# STM32U335 register map
File version: 1.0
CPU: CM33 r0p1, little endian, MPU, FPU, 4 interrupt priority bits
Registers are 32-bit, read-write, reset 0x0 unless marked. A register's access mark holds for its fields unless they carry their own. Offsets are from the block's base; [hi:lo] are bit positions.

## GTZC1_TZIC — GTZC1_TZIC Address block
Base 0x40032800
Same registers: GTZC1_TZIC_S 0x50032800
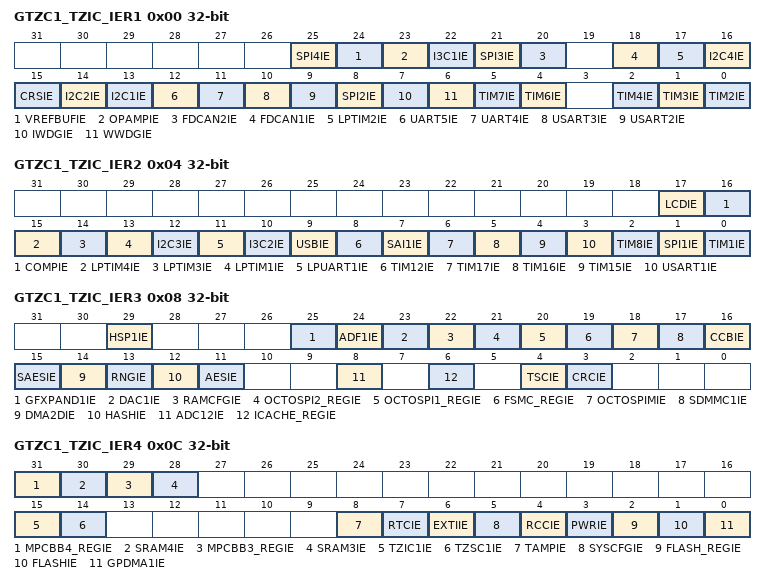
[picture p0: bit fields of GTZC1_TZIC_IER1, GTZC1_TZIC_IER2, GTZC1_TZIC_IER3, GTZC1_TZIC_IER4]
0x00 GTZC1_TZIC_IER1 — Secure privileged access only. This register is used to enable interrupt of illegal access. This register is used to enable interrupt of illegal access.
  [all] fields
    0=interrupt disabled; 1=interrupt enabled
  [25] SPI4IE — illegal access interrupt enable for SPI4 Note: this bit is only available on STM32U3B5/3C5.
  [24] VREFBUFIE — illegal access interrupt enable for VREFBUF Note: this bit is not available on STM32U335/345.
  [23] OPAMPIE — illegal access interrupt enable for OPAMP
  [22] I3C1IE — illegal access interrupt enable for I3C1
  [21] SPI3IE — illegal access interrupt enable for SPI3 Note: this bit is not available on STM32U335/345.
  [20] FDCAN2IE — illegal access interrupt enable for FDCAN2 Note: This bit is only available on STM32U3B5/3C5.
  [18] FDCAN1IE — illegal access interrupt enable for FDCAN1 Note: This bit is not available on STM32U356/366.
  [17] LPTIM2IE — illegal access interrupt enable for LPTIM2
  [16] I2C4IE — illegal access interrupt enable for I2C4 Note: This bit is only available on STM32U3B5/3C5.
  [15] CRSIE — illegal access interrupt enable for CRS
  [14] I2C2IE — illegal access interrupt enable for I2C2 Note: This bit is only available on STM32U375/385, STM32U396/3A6, and STM32U3B5/3C5.
  [13] I2C1IE — illegal access interrupt enable for I2C1
  [12] UART5IE — illegal access interrupt enable for UART5 Note: this bit is not available on STM32U335/345.
  [11] UART4IE — illegal access interrupt enable for UART4
  [10] USART3IE — illegal access interrupt enable for USART3
  [9] USART2IE — illegal access interrupt enable for USART2 Note: This bit is only available on STM32U396/3A6 and STM32U3B5/3C5.
  [8] SPI2IE — illegal access interrupt enable for SPI2
  [7] IWDGIE — illegal access interrupt enable for IWDG
  [6] WWDGIE — illegal access interrupt enable for WWDG
  [5] TIM7IE — illegal access interrupt enable for TIM7 0: interrupt disabled 1: interrupt enabled
  [4] TIM6IE — illegal access interrupt enable for TIM6 0: interrupt disabled 1: interrupt enabled
  [2] TIM4IE — illegal access interrupt enable for TIM4 0: interrupt disabled 1: interrupt enabled
  [1] TIM3IE — illegal access interrupt enable for TIM3 0: interrupt disabled 1: interrupt enabled
  [0] TIM2IE — illegal access interrupt enable for TIM2 0: interrupt disabled 1: interrupt enabled
0x04 GTZC1_TZIC_IER2 — Secure privileged access only. This register is used to enable interrupt of illegal access. This register is used to enable interrupt of illegal access.
  [all] fields
    0=interrupt disabled; 1=interrupt enabled
  [17] LCDIE — illegal access interrupt enable for LCD Note: This bit is only available on STM32U356/366 and STM32U396/3A6.
  [16] COMPIE — illegal access interrupt enable for COMP
  [15] LPTIM4IE — illegal access interrupt enable for LPTIM4 0: interrupt disabled 1: interrupt enabled
  [14] LPTIM3IE — illegal access interrupt enable for LPTIM3 0: interrupt disabled 1: interrupt enabled
  [13] LPTIM1IE — illegal access interrupt enable for LPTIM1 0: interrupt disabled 1: interrupt enabled
  [12] I2C3IE — illegal access interrupt enable for I2C3
  [11] LPUART1IE — illegal access interrupt enable for LPUART1
  [10] I3C2IE — illegal access interrupt enable for I3C2 Note: This bit is only available on STM32U375/385, STM32U396/3A6, and STM32U3B5/3C5.
  [9] USBIE — illegal access interrupt enable for USB
  [8] TIM12IE — illegal access interrupt enable for TIM12 Note: This bit is only available on STM32U396/3A6 and STM32U3B5/3C5.
  [7] SAI1IE — illegal access interrupt enable for SAI1 Note: This bit is only available on STM32U375/385, STM32U396/3A6, and STM32U3B5/3C5.
  [6] TIM17IE — illegal access interrupt enable for TIM17 0: interrupt disabled 1: interrupt enabled
  [5] TIM16IE — illegal access interrupt enable for TIM16 0: interrupt disabled 1: interrupt enabled
  [4] TIM15IE — illegal access interrupt enable for TIM15 0: interrupt disabled 1: interrupt enabled
  [3] USART1IE — illegal access interrupt enable for USART1
  [2] TIM8IE — illegal access interrupt enable for TIM8 Note: This bit is only available on STM32U396/3A6, and STM32U3B5/3C5.
  [1] SPI1IE — illegal access interrupt enable for SPI1
  [0] TIM1IE — illegal access interrupt enable for TIM1 0: interrupt disabled 1: interrupt enabled
0x08 GTZC1_TZIC_IER3 — Secure privileged access only. This register is used to enable interrupt of illegal access. This register is used to enable interrupt of illegal access.
  [all] fields
    0=interrupt disabled; 1=interrupt enabled
  [29] HSP1IE — illegal access interrupt enable for HSP1 Note: This bit is only available on STM32U396/3A6 and STM32U3B5/3C5.
  [25] GFXPAND1IE — illegal access interrupt enable for GFXPAND1 Note: This bit is only available on STM32U396/3A6.
  [24] ADF1IE — illegal access interrupt enable for ADF1 Note: This bit is not available on STM32U356/366.
  [23] DAC1IE — illegal access interrupt enable for DAC1
  [22] RAMCFGIE — illegal access interrupt enable for RAMCFG
  [21] OCTOSPI2_REGIE — illegal access interrupt enable for OCTOSPI2 registers Note: This bit is only available on STM32U396/3A6.
  [20] OCTOSPI1_REGIE — illegal access interrupt enable for OCTOSPI1 registers
  [19] FSMC_REGIE — illegal access interrupt enable for FSMC registers Note: This bit is only available on STM32U396/3A6.
  [18] OCTOSPIMIE — illegal access interrupt enable for OCTOSPIM Note: This bit is only available on STM32U396/3A6.
  [17] SDMMC1IE — illegal access interrupt enable for SDMMC1 Note: This bit is only available on STM32U375/385, STM32U396/3A6, and STM32U3B5/3C5.
  [16] CCBIE — illegal access interrupt enable for CCB Note: This bit is not available on STM32U335/345.
  [15] SAESIE — illegal access interrupt enable for SAES Note: This bit is not available on STM32U335/345.
  [14] DMA2DIE — illegal access interrupt enable for DMA2D Note: This bit is only available on STM32U396/3A6.
  [13] RNGIE — illegal access interrupt enable for RNG
  [12] HASHIE — illegal access interrupt enable for HASH
  [11] AESIE — illegal access interrupt enable for AES
  [8] ADC12IE — illegal access interrupt enable for ADC1 and ADC2
  [6] ICACHE_REGIE — illegal access interrupt enable for ICACHE registers
  [4] TSCIE — illegal access interrupt enable for TSC
  [3] CRCIE — illegal access interrupt enable for CRC
0x0C GTZC1_TZIC_IER4 — Secure privileged access only. This register is used to enable interrupt of illegal access. This register is used to enable interrupt of illegal access.
  [all] fields
    0=interrupt disabled; 1=interrupt enabled
  [31] MPCBB4_REGIE — illegal access interrupt enable for MPCBB4 registers 0: interrupt disabled 1: interrupt enabled Note: This bit is only available on STM32U396/3A6 and STM32U3B5/3C5.
  [30] SRAM4IE — illegal access interrupt enable for SRAM4 0: interrupt disabled 1: interrupt enabled Note: This bit is only available on STM32U396/3A6 and STM32U3B5/3C5.
  [29] MPCBB3_REGIE — illegal access interrupt enable for MPCBB3 registers 0: interrupt disabled 1: interrupt enabled Note: This bit is only available on STM32U396/3A6 and STM32U3B5/3C5.
  [28] SRAM3IE — illegal access interrupt enable for SRAM3 0: interrupt disabled 1: interrupt enabled Note: This bit is only available on STM32U396/3A6 and STM32U3B5/3C5.
  [15] TZIC1IE — illegal access interrupt enable for GTZC1 TZIC registers
  [14] TZSC1IE — illegal access interrupt enable for GTZC1 TZSC registers
  [8] TAMPIE — illegal access interrupt enable for TAMP
  [7] RTCIE — illegal access interrupt enable for RTC
  [6] EXTIIE — illegal access interrupt enable for EXTI
  [5] SYSCFGIE — illegal access interrupt enable for SYSCFG
  [4] RCCIE — illegal access interrupt enable for RCC
  [3] PWRIE — illegal access interrupt enable for PWR
  [2] FLASH_REGIE — illegal access interrupt enable for FLASH registers
  [1] FLASHIE — illegal access interrupt enable for FLASH memory
  [0] GPDMA1IE — illegal access interrupt enable for GPDMA1
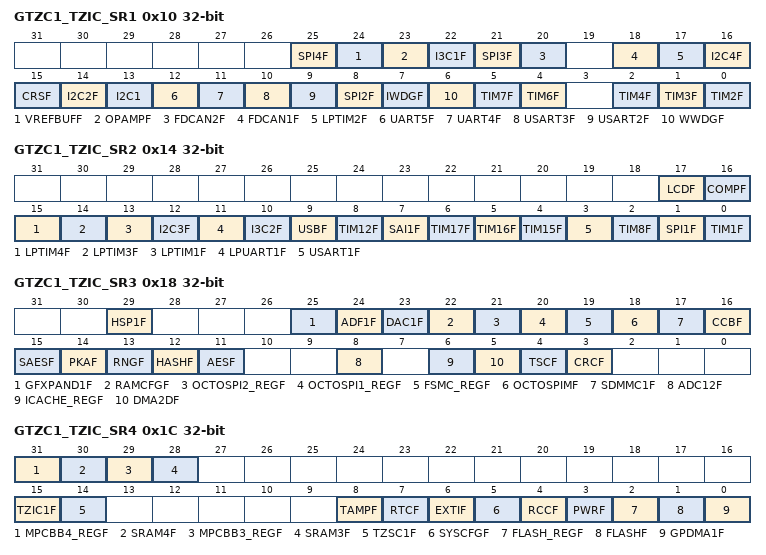
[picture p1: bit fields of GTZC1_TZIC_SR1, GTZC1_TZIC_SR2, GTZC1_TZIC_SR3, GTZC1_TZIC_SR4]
0x10 GTZC1_TZIC_SR1 — Secure privileged access only.
  [all] fields
    0=no illegal access event; 1=illegal access event
  [25] SPI4F — illegal access flag for SPI4 Note: this bit is only available on STM32U3B5/3C5.
  [24] VREFBUFF — illegal access flag for VREFBUF Note: this bit is not available on STM32U335/345.
  [23] OPAMPF — illegal access flag for OPAMP
  [22] I3C1F — illegal access flag for I3C1
  [21] SPI3F — illegal access flag for SPI3 Note: this bit is not available on STM32U335/345.
  [20] FDCAN2F — illegal access flag for FDCAN2 Note: This bit is only available on STM32U3B5/3C5.
  [18] FDCAN1F — illegal access flag for FDCAN1 Note: This bit is not available on STM32U356/366.
  [17] LPTIM2F — illegal access flag for LPTIM2
  [16] I2C4F — illegal access flag for I2C4 Note: This bit is only available on STM32U3B5/3C5.
  [15] CRSF — illegal access flag for CRS
  [14] I2C2F — illegal access flag for I2C2 Note: This bit is only available on STM32U375/385, STM32U396/3A6, and STM32U3B5/3C5.
  [13] I2C1 — illegal access flag for I2C1
  [12] UART5F — illegal access flag for UART5 Note: this bit is not available on STM32U335/345.
  [11] UART4F — illegal access flag for UART4
  [10] USART3F — illegal access flag for USART3
  [9] USART2F — illegal access flag for USART2 Note: This bit is only available on STM32U396/3A6 and STM32U3B5/3C5.
  [8] SPI2F — illegal access flag for SPI2
  [7] IWDGF — illegal access flag for IWDG
  [6] WWDGF — illegal access flag for WWDG
  [5] TIM7F — illegal access flag for TIM7 0: no illegal access event 1: illegal access event
  [4] TIM6F — illegal access flag for TIM6 0: no illegal access event 1: illegal access event
  [2] TIM4F — illegal access flag for TIM4 0: no illegal access event 1: illegal access event
  [1] TIM3F — illegal access flag for TIM3 0: no illegal access event 1: illegal access event
  [0] TIM2F — illegal access flag for TIM2 0: no illegal access event 1: illegal access event
0x14 GTZC1_TZIC_SR2 — Secure privileged access only.
  [all] fields
    0=no illegal access event; 1=illegal access event
  [17] LCDF — illegal access flag for LCD Note: This bit is only available on STM32U356/366 and STM32U396/3A6.
  [16] COMPF — illegal access flag for COMP
  [15] LPTIM4F — illegal access flag for LPTIM4 0: no illegal access event 1: illegal access event
  [14] LPTIM3F — illegal access flag for LPTIM3 0: no illegal access event 1: illegal access event
  [13] LPTIM1F — illegal access flag for LPTIM1 0: no illegal access event 1: illegal access event
  [12] I2C3F — illegal access flag for I2C3
  [11] LPUART1F — illegal access flag for LPUART1
  [10] I3C2F — illegal access flag for I3C2 Note: This bit is only available on STM32U375/385, STM32U396/3A6, and STM32U3B5/3C5.
  [9] USBF — illegal access flag for USB
  [8] TIM12F — illegal access flag for TIM12 Note: This bit is only available on STM32U396/3A6 and STM32U3B5/3C5.
  [7] SAI1F — illegal access flag for SAI1 Note: This bit is only available on STM32U375/385, STM32U396/3A6, and STM32U3B5/3C5.
  [6] TIM17F — illegal access flag for TIM17 0: no illegal access event 1: illegal access event
  [5] TIM16F — illegal access flag for TIM16 0: no illegal access event 1: illegal access event
  [4] TIM15F — illegal access flag for TIM15 0: no illegal access event 1: illegal access event
  [3] USART1F — illegal access flag for USART1
  [2] TIM8F — illegal access flag for TIM8 Note: This bit is only available on STM32U396/3A6, and STM32U3B5/3C5.
  [1] SPI1F — illegal access flag for SPI1
  [0] TIM1F — illegal access flag for TIM1 0: no illegal access event 1: illegal access event
0x18 GTZC1_TZIC_SR3 — Secure privileged access only.
  [all] fields
    0=no illegal access event; 1=illegal access event
  [29] HSP1F — illegal access flag for HSP1 Note: This bit is only available on STM32U396/3A6 and STM32U3B5/3C5
  [25] GFXPAND1F — illegal access flag for GFXPAND1 Note: This bit is only available on STM32U396/3A6.
  [24] ADF1F — illegal access flag for ADF1 Note: This bit is not available on STM32U356/366.
  [23] DAC1F — illegal access flag for DAC1
  [22] RAMCFGF — illegal access flag for RAMCFG
  [21] OCTOSPI2_REGF — illegal access flag for OCTOSPI2 registers Note: This bit is only available on STM32U396/3A6.
  [20] OCTOSPI1_REGF — illegal access flag for OCTOSPI1 registers
  [19] FSMC_REGF — illegal access flag for FSMC registers Note: This bit is only available on STM32U396/3A6.
  [18] OCTOSPIMF — illegal access flag for OCTOSPIM Note: This bit is only available on STM32U396/3A6.
  [17] SDMMC1F — illegal access flag for SDMMC1 Note: This bit is only available on STM32U375/385, STM32U396/3A6, and STM32U3B5/3C5.
  [16] CCBF — illegal access flag for CCB Note: This bit is not available on STM32U335/345.
  [15] SAESF — illegal access flag for SAES Note: This bit is not available on STM32U335/345.
  [14] PKAF — illegal access flag for PKA Note: This bit is not available on STM32U335/345.
  [13] RNGF — illegal access flag for RNG
  [12] HASHF — illegal access flag for HASH
  [11] AESF — illegal access flag for AES
  [8] ADC12F — illegal access flag for ADC1 and ADC2
  [6] ICACHE_REGF — illegal access flag for ICACHE registers
  [5] DMA2DF — illegal access flag for DMA2D Note: This bit is only available on STM32U396/3A6.
  [4] TSCF — illegal access flag for TSC
  [3] CRCF — illegal access flag for CRC
0x1C GTZC1_TZIC_SR4 — Secure privileged access only.
  [all] fields
    0=no illegal access event; 1=illegal access event
  [31] MPCBB4_REGF — illegal access flag for MPCBB4 registers 0: no illegal access event 1: illegal access event Note: This bit is only available on STM32U396/3A6 and STM32U3B5/3C5.
  [30] SRAM4F — illegal access flag for SRAM4 0: no illegal access event 1: illegal access event Note: This bit is only available on STM32U396/3A6 and STM32U3B5/3C5.
  [29] MPCBB3_REGF — illegal access flag for MPCBB3 registers 0: no illegal access event 1: illegal access event Note: This bit is only available on STM32U396/3A6 and STM32U3B5/3C5.
  [28] SRAM3F — illegal access flag for SRAM3 0: no illegal access event 1: illegal access event Note: This bit is only available on STM32U396/3A6 and STM32U3B5/3C5.
  [15] TZIC1F — illegal access flag for GTZC1 TZIC registers
  [14] TZSC1F — illegal access flag for GTZC1 TZSC registers
  [8] TAMPF — illegal access flag for TAMP
  [7] RTCF — illegal access flag for RTC
  [6] EXTIF — illegal access flag for EXTI
  [5] SYSCFGF — illegal access flag for SYSCFG
  [4] RCCF — illegal access flag for RCC
  [3] PWRF — illegal access flag for PWR
  [2] FLASH_REGF — illegal access flag for FLASH registers
  [1] FLASHF — illegal access flag for FLASH memory
  [0] GPDMA1F — illegal access flag for GPDMA1
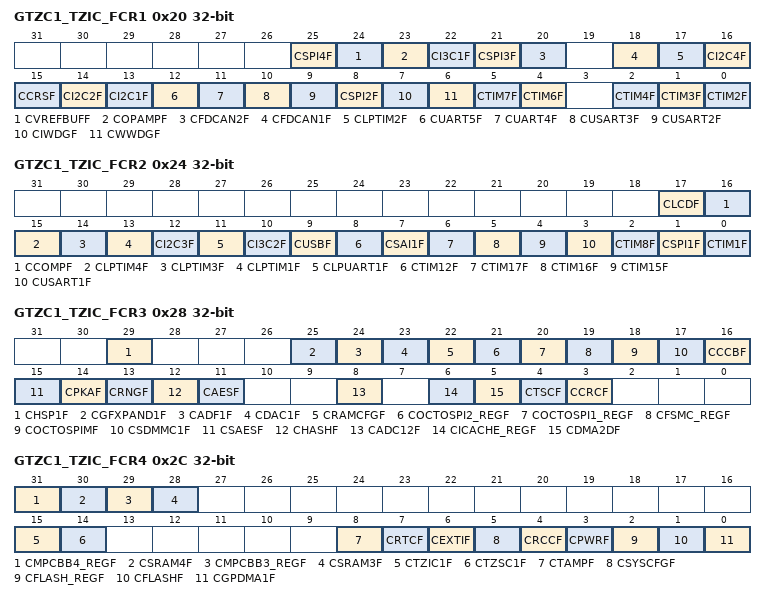
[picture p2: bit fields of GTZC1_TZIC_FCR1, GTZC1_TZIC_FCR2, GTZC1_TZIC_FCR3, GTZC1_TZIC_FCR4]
0x20 GTZC1_TZIC_FCR1 — Secure privileged access only.
  [all] fields
    0=no action; 1=status flag cleared
  [25] CSPI4F — clear the illegal access flag for SPI4 Note: this bit is only available on STM32U3B5/3C5.
  [24] CVREFBUFF — clear the illegal access flag for VREFBUF Note: this bit is not available on STM32U335/345.
  [23] COPAMPF — clear the illegal access flag for OPAMP
  [22] CI3C1F — clear the illegal access flag for I3C1
  [21] CSPI3F — clear the illegal access flag for SPI3 Note: this bit is not available on STM32U335/345.
  [20] CFDCAN2F — clear the illegal access flag for FDCAN2 Note: This bit is only available on STM32U3B5/3C5.
  [18] CFDCAN1F — clear the illegal access flag for FDCAN1 Note: This bit is not available on STM32U356/366.
  [17] CLPTIM2F — clear the illegal access flag for LPTIM2
  [16] CI2C4F — clear the illegal access flag for I2C4 Note: This bit is only available on STM32U3B5/3C5.
  [15] CCRSF — clear the illegal access flag for CRS
  [14] CI2C2F — clear the illegal access flag for I2C2 Note: This bit is only available on STM32U375/385, STM32U396/3A6, and STM32U3B5/3C5.
  [13] CI2C1F — clear the illegal access flag for I2C1
  [12] CUART5F — clear the illegal access flag for UART5 Note: this bit is not available on STM32U335/345.
  [11] CUART4F — clear the illegal access flag for UART4
  [10] CUSART3F — clear the illegal access flag for USART3
  [9] CUSART2F — clear the illegal access flag for USART2 Note: This bit is only available on STM32U396/3A6 and STM32U3B5/3C5.
  [8] CSPI2F — clear the illegal access flag for SPI2
  [7] CIWDGF — clear the illegal access flag for IWDG
  [6] CWWDGF — clear the illegal access flag for WWDG
  [5] CTIM7F — clear the illegal access flag for TIM7 0: no action 1: status flag cleared
  [4] CTIM6F — clear the illegal access flag for TIM6 0: no action 1: status flag cleared
  [2] CTIM4F — clear the illegal access flag for TIM4 0: no action 1: status flag cleared
  [1] CTIM3F — clear the illegal access flag for TIM3 0: no action 1: status flag cleared
  [0] CTIM2F — clear the illegal access flag for TIM2 0: no action 1: status flag cleared
0x24 GTZC1_TZIC_FCR2 — Secure privileged access only.
  [all] fields
    0=no action; 1=status flag cleared
  [17] CLCDF — clear the illegal access flag for LCD Note: This bit is only available on STM32U356/366 and STM32U396/3A6.
  [16] CCOMPF — clear the illegal access flag for COMP
  [15] CLPTIM4F — clear the illegal access flag for LPTIM4 0: no action 1: status flag cleared
  [14] CLPTIM3F — clear the illegal access flag for LPTIM3 0: no action 1: status flag cleared
  [13] CLPTIM1F — clear the illegal access flag for LPTIM1 0: no action 1: status flag cleared
  [12] CI2C3F — clear the illegal access flag for I2C3
  [11] CLPUART1F — clear the illegal access flag for LPUART1
  [10] CI3C2F — clear the illegal access flag for I3C2 Note: This bit is only available on STM32U375/385, STM32U396/3A6, and STM32U3B5/3C5.
  [9] CUSBF — clear the illegal access flag for USB
  [8] CTIM12F — clear the illegal access flag for TIM12 Note: This bit is only available on STM32U396/3A6 and STM32U3B5/3C5.
  [7] CSAI1F — clear the illegal access flag for SAI1 Note: This bit is only available on STM32U375/385, STM32U396/3A6, and STM32U3B5/3C5.
  [6] CTIM17F — clear the illegal access flag for TIM17 0: no action 1: status flag cleared
  [5] CTIM16F — clear the illegal access flag for TIM16 0: no action 1: status flag cleared
  [4] CTIM15F — clear the illegal access flag for TIM15 0: no action 1: status flag cleared
  [3] CUSART1F — clear the illegal access flag for USART1
  [2] CTIM8F — clear the illegal access flag for TIM8 Note: This bit is only available on STM32U396/3A6, and STM32U3B5/3C5.
  [1] CSPI1F — clear the illegal access flag for SPI1
  [0] CTIM1F — clear the illegal access flag for TIM1 0: no action 1: status flag cleared
0x28 GTZC1_TZIC_FCR3 — Secure privilege access only.
  [all] fields
    0=no action; 1=status flag cleared
  [29] CHSP1F — clear the illegal access flag for HSP1 Note: This bit is only available on STM32U396/3A6 and STM32U3B5/3C5
  [25] CGFXPAND1F — clear the illegal access flag for GFXPAND1 Note: This bit is only available on STM32U396/3A6.
  [24] CADF1F — clear the illegal access flag for ADF1 Note: This bit is not available on STM32U356/366.
  [23] CDAC1F — clear the illegal access flag for DAC1
  [22] CRAMCFGF — clear the illegal access flag for RAMCFG
  [21] COCTOSPI2_REGF — clear the illegal access flag for OCTOSPI2 registers Note: This bit is only available on STM32U396/3A6.
  [20] COCTOSPI1_REGF — clear the illegal access flag for OCTOSPI1 registers
  [19] CFSMC_REGF — clear the illegal access flag for FSMC registers Note: This bit is only available on STM32U396/3A6.
  [18] COCTOSPIMF — clear the illegal access flag for OCTOSPIM Note: This bit is only available on STM32U396/3A6.
  [17] CSDMMC1F — clear the illegal access flag for SDMMC1 Note: This bit is only available on STM32U375/385, STM32U396/3A6, and STM32U3B5/3C5.
  [16] CCCBF — clear the illegal access flag for CCB Note: This bit is not available on STM32U335/345.
  [15] CSAESF — clear the illegal access flag for SAES Note: This bit is not available on STM32U335/345.
  [14] CPKAF — clear the illegal access flag for PKA Note: This bit is not available on STM32U335/345.
  [13] CRNGF — clear the illegal access flag for RNG
  [12] CHASHF — clear the illegal access flag for HASH
  [11] CAESF — clear the illegal access flag for AES
  [8] CADC12F — clear the illegal access flag for ADC1 and ADC2
  [6] CICACHE_REGF — clear the illegal access flag for ICACHE registers
  [5] CDMA2DF — clear the illegal access flag for DMA2D Note: This bit is only available on STM32U396/3A6.
  [4] CTSCF — clear the illegal access flag for TSC
  [3] CCRCF — clear the illegal access flag for CRC
0x2C GTZC1_TZIC_FCR4 — Secure privilege access only.
  [all] fields
    0=no action; 1=status flag cleared
  [31] CMPCBB4_REGF — clear the illegal access flag for MPCBB4 registers 0: no action 1: status flag cleared Note: This bit is only available on STM32U396/3A6 and STM32U3B5/3C5.
  [30] CSRAM4F — clear the illegal access flag for SRAM4 0: no action 1: status flag cleared Note: This bit is only available on STM32U396/3A6 and STM32U3B5/3C5.
  [29] CMPCBB3_REGF — clear the illegal access flag for MPCBB3 registers 0: no action 1: status flag cleared Note: This bit is only available on STM32U396/3A6 and STM32U3B5/3C5.
  [28] CSRAM3F — clear the illegal access flag for SRAM3 0: no action 1: status flag cleared Note: This bit is only available on STM32U396/3A6 and STM32U3B5/3C5.
  [15] CTZIC1F — clear the illegal access flag for GTZC1 TZIC registers
  [14] CTZSC1F — clear the illegal access flag for GTZC1 TZSC registers
  [8] CTAMPF — clear the illegal access flag for TAMP
  [7] CRTCF — clear the illegal access flag for RTC
  [6] CEXTIF — clear the illegal access flag for EXTI
  [5] CSYSCFGF — clear the illegal access flag for SYSCFG
  [4] CRCCF — clear the illegal access flag for RCC
  [3] CPWRF — clear the illegal access flag for PWR
  [2] CFLASH_REGF — clear the illegal access flag for FLASH registers
  [1] CFLASHF — clear the illegal access flag for FLASH memory
  [0] CGPDMA1F — clear the illegal access flag for GPDMA1
